# IND83215A register map
Series: Verne; File version: A0
CPU: CM0 r0p1, selectable endian, no MPU, no FPU, 4 interrupt priority bits
Registers are 32-bit, read-write, no defined reset value unless marked. A register's access mark holds for its fields unless they carry their own. Offsets are from the block's base; [hi:lo] are bit positions.

## UART0 — UART Interface registers
Base 0x50015400; register names take the prefix UART0_
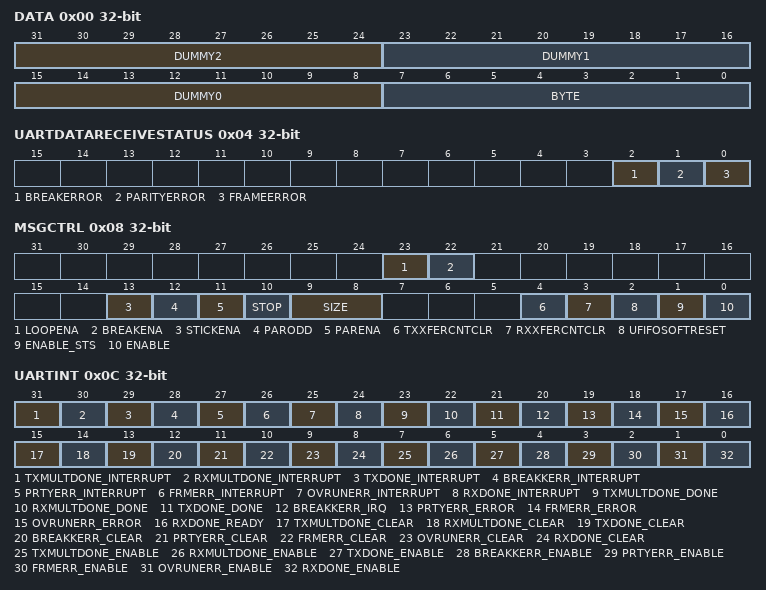
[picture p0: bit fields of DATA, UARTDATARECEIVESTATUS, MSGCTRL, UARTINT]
0x00 DATA
  [31:24] DUMMY2 dual — Data. Used for both received data and data that is to be transmitted.
  [23:16] DUMMY1 dual — Data. Used for both received data and data that is to be transmitted.
  [15:8] DUMMY0 dual — Data. Used for both received data and data that is to be transmitted.
  [7:0] BYTE dual — Data. Used for both received data and data that is to be transmitted.
0x04 UARTDATARECEIVESTATUS — Data Receive Status
  [2] BREAKERROR ro — Break Error. This bit is set to 1 if a break condition was detected, indicating that the received data input was held LOW for longer than a full-word transmission time (defined as start, data, parity, and stop bits).
  [1] PARITYERROR ro — Parity Error. When this bit is set to 1, it indicates that the parity of the received data character has parity error.
  [0] FRAMEERROR ro — Framing Error. When this bit is set to 1, it indicates that the received byte did not have a valid stop bit (a valid stop bit is 1).
0x08 MSGCTRL — Message control
  [23] LOOPENA — Loopback enable. Set to enable loopback
  [22] BREAKENA — Break enable. Set to force transmission of zero (for a break condition)
  [13] STICKENA — Sticky parity enable. Set to enable sticky parity
  [12] PARODD — Odd parity. 0x0: ODD Parity 0x1: EVEN parity
  [11] PARENA — Parity enable. Set to enable parity (see PARODD for odd/even)
  [10] STOP — Stop bit control. 0x0: One stop bit 0x1: If a 5-bit transmission it selects 1.5 stop bits, otherwise 2 stop bits (6, 7 & 8 bits)
  [9:8] SIZE — Transmission word size. 0x0: 5-bit 0x1: 6-bit 0x2: 7-bit 0x3: 8-bit
  [4] TXXFERCNTCLR wo — TX Transfer Counter Clear. Clear TX Multi Transfer Counter to zero Autoclear: includes a synchronous reset signal which clears the register on the cycle following write.
  [3] RXXFERCNTCLR wo — RX Transfer Counter Clear. Clear RX Multi Transfer Counter to zero Autoclear: includes a synchronous reset signal which clears the register on the cycle following write.
  [2] UFIFOSOFTRESET wo — FIFO SOFT RESET. Resets FIFO pointers to zero and initializes FIFO contents to zero Autoclear: includes a synchronous reset signal which clears the register on the cycle following write.
  [1] ENABLE_STS ro — Enable status. Status of UART enable
  [0] ENABLE — Enable. Set to enable the UART
0x0C UARTINT — UART Interrupts
  [31] TXMULTDONE_INTERRUPT ro — Multiple Transmit Transactions Done Interrupt. Set by the UART when the programmed number of transmit transactions have completed. See UART_FIFO_LEVEL_CTL register.
  [30] RXMULTDONE_INTERRUPT ro — Multiple Receive Transactions Done Interrupt. Set by the UART when the programmed number of receive transactions have completed. See UART_FIFO_LEVEL_CTL register
  [29] TXDONE_INTERRUPT ro — Transmission done Interrupt. Set by the UART when the transmission is done
  [28] BREAKKERR_INTERRUPT ro — Break Error Interrupt. Set by the UART when a break error occurs
  [27] PRTYERR_INTERRUPT ro — Parity Error Interrupt. Set by the UART when a parity error occurs
  [26] FRMERR_INTERRUPT ro — Framing error Interrupt. Set by the UART when a framing error occurs
  [25] OVRUNERR_INTERRUPT ro — RX FIFO overflow error Interrupt. Set by the UART when an overrun error occurs
  [24] RXDONE_INTERRUPT ro — Rx Data ready Interrupt. Set by the UART when Rx data is ready
  [23] TXMULTDONE_DONE ro — Multiple Transmit Transactions Done. Set by the UART when the programmed number of transmit transactions have completed. See UART_FIFO_LEVEL_CTL register.
  [22] RXMULTDONE_DONE ro — Multiple Receive Transactions Done. Set by the UART when the programmed number of receive transactions have completed. See UART_FIFO_LEVEL_CTL register
  [21] TXDONE_DONE ro — Transmission is done. Set by the UART when the transmit is done
  [20] BREAKKERR_IRQ ro — Break IRQ. Set by the UART when a break error occurs
  [19] PRTYERR_ERROR ro — Parity Error. Set by the UART when a parity error occurs
  [18] FRMERR_ERROR ro — Framing error. Set by the UART when a framing error occurs
  [17] OVRUNERR_ERROR ro — RX FIFO overflow error. Set by the UART when an overrun error occurs
  [16] RXDONE_READY ro — Rx Data ready. Set by the UART when Rx data is ready
  [15] TXMULTDONE_CLEAR wo — Multiple Transmit Transactions Done Interrupt Clear. Autoclear: includes a synchronous reset signal which clears the register on the cycle following write.
  [14] RXMULTDONE_CLEAR wo — Multiple Receive Transactions Done Interrupt Clear. Autoclear: includes a synchronous reset signal which clears the register on the cycle following write.
  [13] TXDONE_CLEAR wo — Transmission done Interrupt Clear. Autoclear: includes a synchronous reset signal which clears the register on the cycle following write.
  [12] BREAKKERR_CLEAR wo — Break Error Interrupt Clear. Autoclear: includes a synchronous reset signal which clears the register on the cycle following write.
  [11] PRTYERR_CLEAR wo — Parity Error Interrupt Clear. Autoclear: includes a synchronous reset signal which clears the register on the cycle following write.
  [10] FRMERR_CLEAR wo — Framing error Interrupt Clear. Autoclear: includes a synchronous reset signal which clears the register on the cycle following write.
  [9] OVRUNERR_CLEAR wo — RX FIFO overflow error Interrupt Clear. Autoclear: includes a synchronous reset signal which clears the register on the cycle following write.
  [8] RXDONE_CLEAR wo — Rx Data ready Interrupt Clear. Autoclear: includes a synchronous reset signal which clears the register on the cycle following write.
  [7] TXMULTDONE_ENABLE — Multiple Transmit Transactions Done Interrupt Enable.
  [6] RXMULTDONE_ENABLE — Multiple Receive Transactions Done Interrupt Enable.
  [5] TXDONE_ENABLE — Transmission done Interrupt Enable.
  [4] BREAKKERR_ENABLE — Break Error Interrupt Enable.
  [3] PRTYERR_ENABLE — Parity Error Interrupt Enable.
  [2] FRMERR_ENABLE — Framing error Interrupt Enable.
  [1] OVRUNERR_ENABLE — RX FIFO overflow error Interrupt Enable.
  [0] RXDONE_ENABLE — Rx Data ready Interrupt Enable.
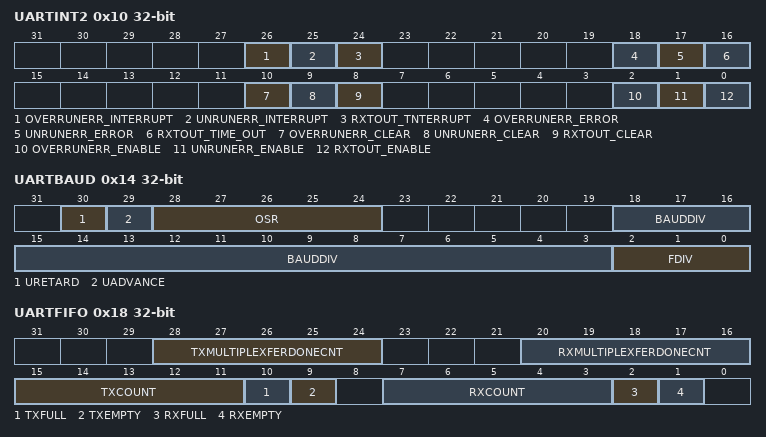
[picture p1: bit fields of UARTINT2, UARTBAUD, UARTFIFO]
0x10 UARTINT2 — Extended UART Interrupts
  [26] OVERRUNERR_INTERRUPT ro — TX FIFO overflow error Interrupt. Set by the UART when an TX FIFO overflow error interrupt occurs.
  [25] UNRUNERR_INTERRUPT ro — RX FIFO underflow error Interrupt. Set by the UART when an under flow error interrupt occurs.
  [24] RXTOUT_TNTERRUPT ro — Rx Time-out Interrupt. Set by the UART when RXTOUT flag is set and RXOUT interrupt is enabled.
  [18] OVERRUNERR_ERROR ro — TX FIFO overflow error. Set by the UART when an TX FIFO overflow error occurs.
  [17] UNRUNERR_ERROR ro — RX FIFO underflow error. Set by the UART when an under flow error occurs.
  [16] RXTOUT_TIME_OUT ro — Rx Time-out. Set by the UART when timeout of 4 data frame times without reception, and data received(one or three bytes received,programmable)
  [10] OVERRUNERR_CLEAR wo — TX FIFO overflow error Interrupt Clear. Autoclear: includes a synchronous reset signal which clears the register on the cycle following write.
  [9] UNRUNERR_CLEAR wo — RX FIFO underflow error Interrupt Clear. Autoclear: includes a synchronous reset signal which clears the register on the cycle following write.
  [8] RXTOUT_CLEAR wo — Rx Time-out Interrupt Clear. Autoclear: includes a synchronous reset signal which clears the register on the cycle following write.
  [2] OVERRUNERR_ENABLE — TX FIFO overflow error Interrupt Enable.
  [1] UNRUNERR_ENABLE — RX FIFO underflow error Interrupt Enable.
  [0] RXTOUT_ENABLE — Rx Time-out Interrupt Enable.
0x14 UARTBAUD — UART Baud rate
  [30] URETARD — Retard Register. Retards the sample window by 1 cycle. For Debug.
  [29] UADVANCE — Advance Register. Advances the sample window by 1 cycle. For Debug.
  [28:24] OSR — Over-sampling ratio. Valid OSR Range: 6 to 16.
  [18:3] BAUDDIV — Baud rate divider.
  [2:0] FDIV — Fractional divider.
0x18 UARTFIFO — UART FIFO interface
  [28:24] TXMULTIPLEXFERDONECNT — Transmit Data Count Interrupt. Number of bytes transmitted from the transmit FIFO before a INT_TX_MULTIPLE_XFER_DONE interrupt is asserted. Example: A value of 4 would be used to compare to the number of completed transfers (pops from the Tx FIFO). Valid Range: 1 to 16
  [20:16] RXMULTIPLEXFERDONECNT — Receive Data Count Interrupt. Minimum number of bytes in the receive FIFO before a INT_RX_MULTIPLE_XFER_DONE interrupt is asserted. Example: A value of 4 would be used to compare to the number of receive transactions (pushes to the Rx FIFO). Valid Range: 1 to 16
  [15:11] TXCOUNT ro — Transmit FIFO current count.
  [10] TXFULL ro — Transmit FIFO full.
  [9] TXEMPTY ro — Transmit FIFO empty.
  [7:3] RXCOUNT ro — Reception FIFO current count.
  [2] RXFULL ro — Reception FIFO full.
  [1] RXEMPTY ro — Reception FIFO empty.
